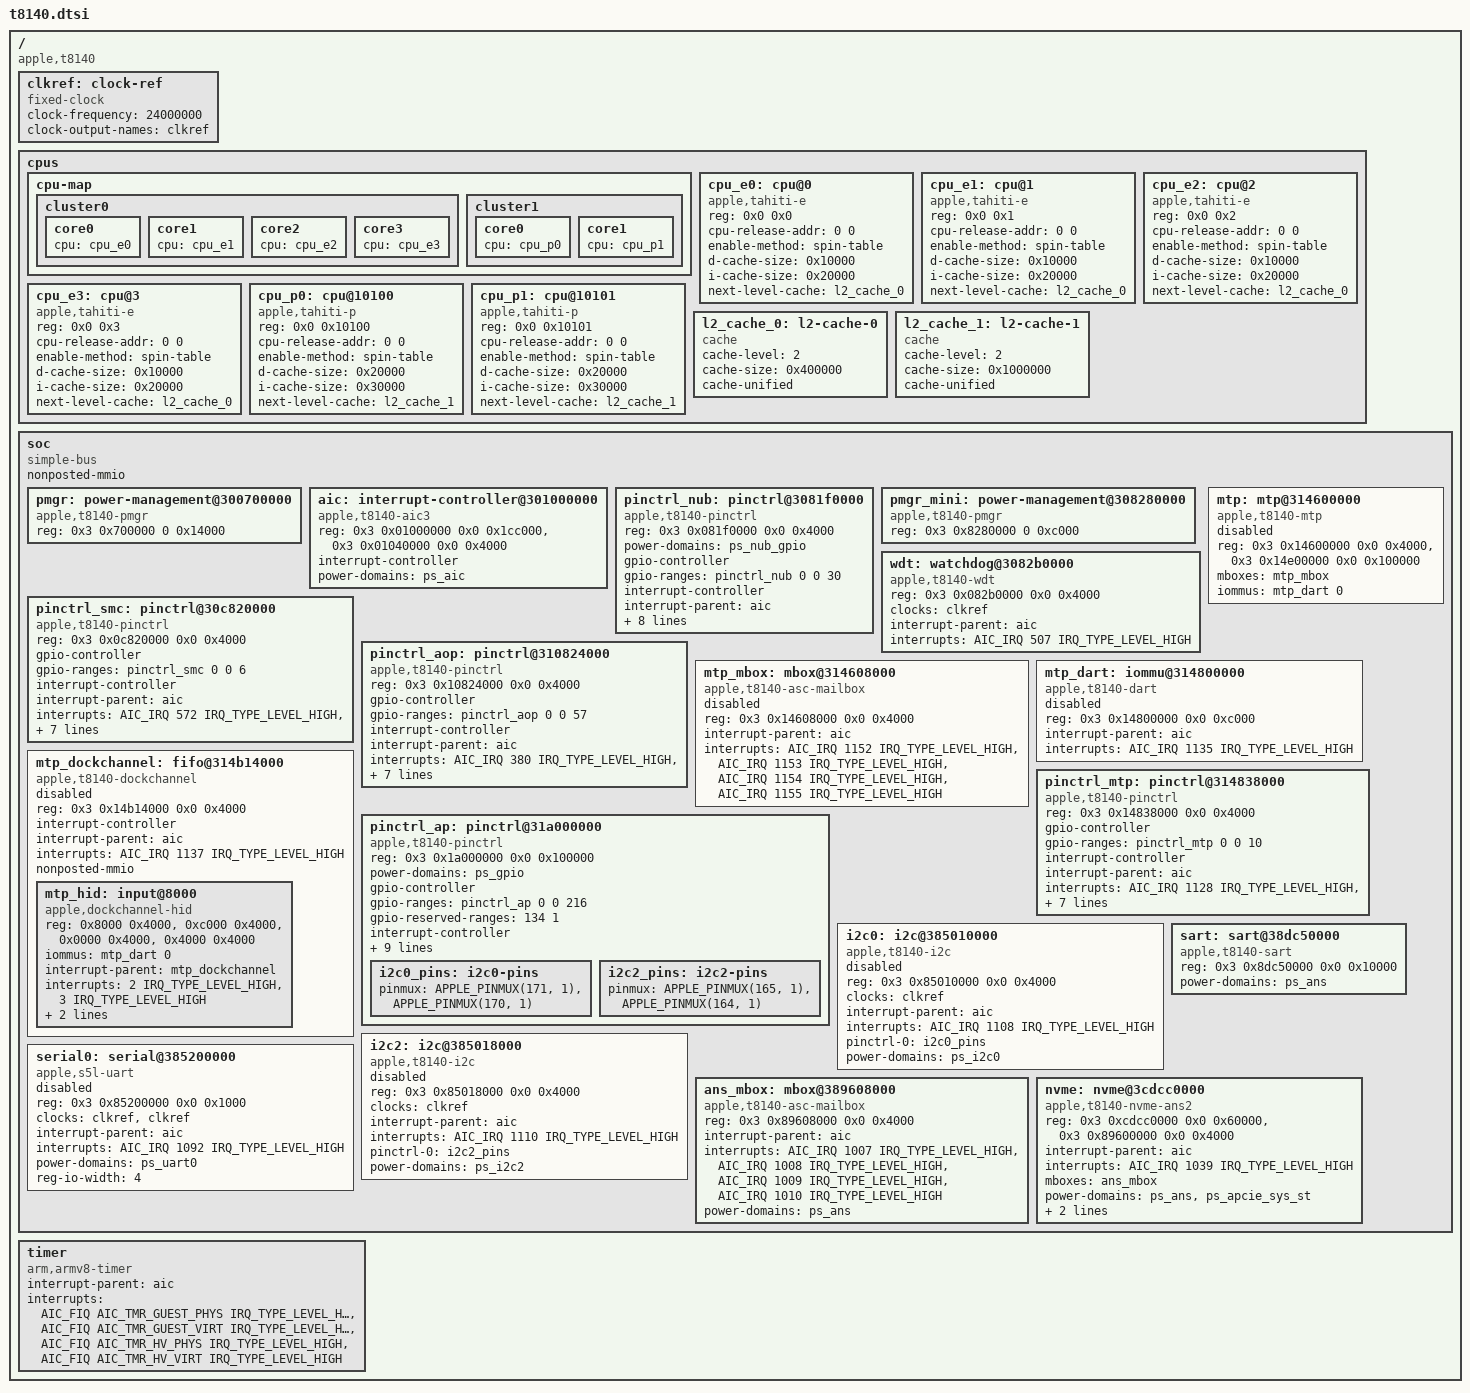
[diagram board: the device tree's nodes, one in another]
// SPDX-License-Identifier: GPL-2.0+ OR MIT
/*
 * Apple T8140 "A18 Pro" SoC
 *
 * Copyright The Asahi Linux Contributors
 */

#include <dt-bindings/interrupt-controller/apple-aic.h>
#include <dt-bindings/interrupt-controller/irq.h>
#include <dt-bindings/pinctrl/apple.h>

/ {
	compatible = "apple,t8140", "apple,arm-platform";

	#address-cells = <2>;
	#size-cells = <2>;

	clkref: clock-ref {
		compatible = "fixed-clock";
		#clock-cells = <0>;
		clock-frequency = <24000000>;
		clock-output-names = "clkref";
	};

	cpus {
		#address-cells = <2>;
		#size-cells = <0>;

		cpu-map {
			cluster0 {
				core0 {
					cpu = <&cpu_e0>;
				};

				core1 {
					cpu = <&cpu_e1>;
				};

				core2 {
					cpu = <&cpu_e2>;
				};

				core3 {
					cpu = <&cpu_e3>;
				};
			};

			cluster1 {
				core0 {
					cpu = <&cpu_p0>;
				};

				core1 {
					cpu = <&cpu_p1>;
				};
			};
		};

		cpu_e0: cpu@0 {
			device_type = "cpu";
			compatible = "apple,tahiti-e";
			reg = <0x0 0x0>;
			cpu-release-addr = <0 0>;
			enable-method = "spin-table";

			d-cache-size = <0x10000>;
			i-cache-size = <0x20000>;
			next-level-cache = <&l2_cache_0>;
		};

		cpu_e1: cpu@1 {
			device_type = "cpu";
			compatible = "apple,tahiti-e";
			reg = <0x0 0x1>;
			cpu-release-addr = <0 0>;
			enable-method = "spin-table";

			d-cache-size = <0x10000>;
			i-cache-size = <0x20000>;
			next-level-cache = <&l2_cache_0>;
		};

		cpu_e2: cpu@2 {
			device_type = "cpu";
			compatible = "apple,tahiti-e";
			reg = <0x0 0x2>;
			cpu-release-addr = <0 0>;
			enable-method = "spin-table";

			d-cache-size = <0x10000>;
			i-cache-size = <0x20000>;
			next-level-cache = <&l2_cache_0>;
		};

		cpu_e3: cpu@3 {
			device_type = "cpu";
			compatible = "apple,tahiti-e";
			reg = <0x0 0x3>;
			cpu-release-addr = <0 0>;
			enable-method = "spin-table";

			d-cache-size = <0x10000>;
			i-cache-size = <0x20000>;
			next-level-cache = <&l2_cache_0>;
		};

		cpu_p0: cpu@10100 {
			device_type = "cpu";
			compatible = "apple,tahiti-p";
			reg = <0x0 0x10100>;
			cpu-release-addr = <0 0>;
			enable-method = "spin-table";

			d-cache-size = <0x20000>;
			i-cache-size = <0x30000>;
			next-level-cache = <&l2_cache_1>;
		};

		cpu_p1: cpu@10101 {
			device_type = "cpu";
			compatible = "apple,tahiti-p";
			reg = <0x0 0x10101>;
			cpu-release-addr = <0 0>;
			enable-method = "spin-table";

			d-cache-size = <0x20000>;
			i-cache-size = <0x30000>;
			next-level-cache = <&l2_cache_1>;
		};

		l2_cache_0: l2-cache-0 {
			compatible = "cache";
			cache-level = <2>;
			cache-size = <0x400000>;
			cache-unified;
		};

		l2_cache_1: l2-cache-1 {
			compatible = "cache";
			cache-level = <2>;
			cache-size = <0x1000000>;
			cache-unified;
		};
	};

	soc: soc {
		compatible = "simple-bus";
		ranges;
		#address-cells = <2>;
		nonposted-mmio;
		#size-cells = <2>;

		pmgr: power-management@300700000 {
			compatible = "apple,t8140-pmgr", "apple,t8103-pmgr",
			             "syscon", "simple-mfd";
			reg = <0x3 0x700000 0 0x14000>;
			#address-cells = <1>;
			#size-cells = <1>;
			/* child nodes are added in t8140-pmgr.dtsi */
		};

		aic: interrupt-controller@301000000 {
			compatible = "apple,t8140-aic3", "apple,t8122-aic3";
			reg = <0x3 0x01000000 0x0 0x1cc000>,
			      <0x3 0x01040000 0x0 0x4000>;
			reg-names = "core", "event";
			#interrupt-cells = <3>;
			interrupt-controller;
			power-domains = <&ps_aic>;
		};

		pinctrl_nub: pinctrl@3081f0000 {
			compatible = "apple,t8140-pinctrl";
			reg = <0x3 0x081f0000 0x0 0x4000>;
			power-domains = <&ps_nub_gpio>;

			gpio-controller;
			#gpio-cells = <2>;
			gpio-ranges = <&pinctrl_nub 0 0 30>;

			interrupt-controller;
			#interrupt-cells = <2>;
			interrupt-parent = <&aic>;
			interrupts = <AIC_IRQ 473 IRQ_TYPE_LEVEL_HIGH>,
			             <AIC_IRQ 474 IRQ_TYPE_LEVEL_HIGH>,
			             <AIC_IRQ 475 IRQ_TYPE_LEVEL_HIGH>,
			             <AIC_IRQ 476 IRQ_TYPE_LEVEL_HIGH>,
			             <AIC_IRQ 477 IRQ_TYPE_LEVEL_HIGH>,
			             <AIC_IRQ 478 IRQ_TYPE_LEVEL_HIGH>,
			             <AIC_IRQ 479 IRQ_TYPE_LEVEL_HIGH>;

			apple,npins = <30>;
		};

		pmgr_mini: power-management@308280000 {
			compatible = "apple,t8140-pmgr", "apple,t8103-pmgr",
			             "syscon", "simple-mfd";
			reg = <0x3 0x8280000 0 0xc000>;
			#address-cells = <1>;
			#size-cells = <1>;
			/* child nodes are added in t8140-pmgr.dtsi */
		};

		wdt: watchdog@3082b0000 {
			compatible = "apple,t8140-wdt", "apple,t8103-wdt";
			reg = <0x3 0x082b0000 0x0 0x4000>;
			clocks = <&clkref>;
			interrupt-parent = <&aic>;
			interrupts = <AIC_IRQ 507 IRQ_TYPE_LEVEL_HIGH>;
		};

		pinctrl_smc: pinctrl@30c820000 {
			compatible = "apple,t8140-pinctrl";
			reg = <0x3 0x0c820000 0x0 0x4000>;

			gpio-controller;
			#gpio-cells = <2>;
			gpio-ranges = <&pinctrl_smc 0 0 6>;

			interrupt-controller;
			#interrupt-cells = <2>;
			interrupt-parent = <&aic>;
			interrupts = <AIC_IRQ 572 IRQ_TYPE_LEVEL_HIGH>,
			             <AIC_IRQ 573 IRQ_TYPE_LEVEL_HIGH>,
			             <AIC_IRQ 574 IRQ_TYPE_LEVEL_HIGH>,
			             <AIC_IRQ 575 IRQ_TYPE_LEVEL_HIGH>,
			             <AIC_IRQ 576 IRQ_TYPE_LEVEL_HIGH>,
			             <AIC_IRQ 577 IRQ_TYPE_LEVEL_HIGH>,
			             <AIC_IRQ 578 IRQ_TYPE_LEVEL_HIGH>;

			apple,npins = <6>;
		};

		pinctrl_aop: pinctrl@310824000 {
			compatible = "apple,t8140-pinctrl";
			reg = <0x3 0x10824000 0x0 0x4000>;

			gpio-controller;
			#gpio-cells = <2>;
			gpio-ranges = <&pinctrl_aop 0 0 57>;

			interrupt-controller;
			#interrupt-cells = <2>;
			interrupt-parent = <&aic>;
			interrupts = <AIC_IRQ 380 IRQ_TYPE_LEVEL_HIGH>,
			             <AIC_IRQ 381 IRQ_TYPE_LEVEL_HIGH>,
			             <AIC_IRQ 382 IRQ_TYPE_LEVEL_HIGH>,
			             <AIC_IRQ 383 IRQ_TYPE_LEVEL_HIGH>,
			             <AIC_IRQ 384 IRQ_TYPE_LEVEL_HIGH>,
			             <AIC_IRQ 385 IRQ_TYPE_LEVEL_HIGH>,
			             <AIC_IRQ 386 IRQ_TYPE_LEVEL_HIGH>;

			apple,npins = <57>;
		};

		mtp: mtp@314600000 {
			compatible = "apple,t8140-mtp",
			             "apple,t8140-rtk-helper-asc4", "apple,mtp",
			             "apple,rtk-helper-asc4";
			reg = <0x3 0x14600000 0x0 0x4000>,
			      <0x3 0x14e00000 0x0 0x100000>;
			reg-names = "asc", "sram";
			mboxes = <&mtp_mbox>;
			iommus = <&mtp_dart 0>;
			#helper-cells = <0>;

			status = "disabled";
		};

		mtp_mbox: mbox@314608000 {
			compatible = "apple,t8140-asc-mailbox",
			             "apple,asc-mailbox-v4";
			reg = <0x3 0x14608000 0x0 0x4000>;
			interrupt-parent = <&aic>;
			interrupts = <AIC_IRQ 1152 IRQ_TYPE_LEVEL_HIGH>,
			             <AIC_IRQ 1153 IRQ_TYPE_LEVEL_HIGH>,
			             <AIC_IRQ 1154 IRQ_TYPE_LEVEL_HIGH>,
			             <AIC_IRQ 1155 IRQ_TYPE_LEVEL_HIGH>;
			interrupt-names = "send-empty", "send-not-empty",
			                  "recv-empty", "recv-not-empty";
			#mbox-cells = <0>;

			status = "disabled";
		};

		mtp_dart: iommu@314800000 {
			compatible = "apple,t8140-dart", "apple,t8110-dart";
			reg = <0x3 0x14800000 0x0 0xc000>;
			interrupt-parent = <&aic>;
			interrupts = <AIC_IRQ 1135 IRQ_TYPE_LEVEL_HIGH>;
			#iommu-cells = <1>;

			status = "disabled";
		};

		pinctrl_mtp: pinctrl@314838000 {
			compatible = "apple,t8140-pinctrl";
			reg = <0x3 0x14838000 0x0 0x4000>;

			gpio-controller;
			#gpio-cells = <2>;
			gpio-ranges = <&pinctrl_mtp 0 0 10>;

			interrupt-controller;
			#interrupt-cells = <2>;
			interrupt-parent = <&aic>;
			interrupts = <AIC_IRQ 1128 IRQ_TYPE_LEVEL_HIGH>,
			             <AIC_IRQ 1129 IRQ_TYPE_LEVEL_HIGH>,
			             <AIC_IRQ 1130 IRQ_TYPE_LEVEL_HIGH>,
			             <AIC_IRQ 1131 IRQ_TYPE_LEVEL_HIGH>,
			             <AIC_IRQ 1132 IRQ_TYPE_LEVEL_HIGH>,
			             <AIC_IRQ 1133 IRQ_TYPE_LEVEL_HIGH>,
			             <AIC_IRQ 1134 IRQ_TYPE_LEVEL_HIGH>;

			apple,npins = <10>;
		};

		mtp_dockchannel: fifo@314b14000 {
			compatible = "apple,t8140-dockchannel",
			             "apple,dockchannel";
			reg = <0x3 0x14b14000 0x0 0x4000>;
			reg-names = "irq";
			ranges = <0 0x3 0x14b28000 0x20000>;

			interrupt-controller;
			#interrupt-cells = <2>;
			interrupt-parent = <&aic>;
			interrupts = <AIC_IRQ 1137 IRQ_TYPE_LEVEL_HIGH>;

			nonposted-mmio;
			#address-cells = <1>;
			#size-cells = <1>;

			status = "disabled";

			mtp_hid: input@8000 {
				compatible = "apple,dockchannel-hid";
				reg = <0x8000 0x4000>,
				      <0xc000 0x4000>,
				      <0x0000 0x4000>,
				      <0x4000 0x4000>;
				reg-names = "config", "data",
				            "rmt-config", "rmt-data";
				iommus = <&mtp_dart 0>;
				interrupt-parent = <&mtp_dockchannel>;
				interrupts = <2 IRQ_TYPE_LEVEL_HIGH>,
				             <3 IRQ_TYPE_LEVEL_HIGH>;
				interrupt-names = "tx", "rx";

				apple,fifo-size = <0x800>;
				apple,helper-cpu = <&mtp>;
			};
		};

		pinctrl_ap: pinctrl@31a000000 {
			compatible = "apple,t8140-pinctrl";
			reg = <0x3 0x1a000000 0x0 0x100000>;
			power-domains = <&ps_gpio>;

			gpio-controller;
			#gpio-cells = <2>;
			gpio-ranges = <&pinctrl_ap 0 0 216>;
			gpio-reserved-ranges = <134 1>;

			interrupt-controller;
			#interrupt-cells = <2>;
			interrupt-parent = <&aic>;
			interrupts = <AIC_IRQ 263 IRQ_TYPE_LEVEL_HIGH>,
			             <AIC_IRQ 264 IRQ_TYPE_LEVEL_HIGH>,
			             <AIC_IRQ 265 IRQ_TYPE_LEVEL_HIGH>,
			             <AIC_IRQ 266 IRQ_TYPE_LEVEL_HIGH>,
			             <AIC_IRQ 267 IRQ_TYPE_LEVEL_HIGH>,
			             <AIC_IRQ 268 IRQ_TYPE_LEVEL_HIGH>,
			             <AIC_IRQ 269 IRQ_TYPE_LEVEL_HIGH>;

			apple,npins = <216>;

			i2c0_pins: i2c0-pins {
				pinmux = <APPLE_PINMUX(171, 1)>,
				         <APPLE_PINMUX(170, 1)>;
			};

			i2c2_pins: i2c2-pins {
				pinmux = <APPLE_PINMUX(165, 1)>,
				         <APPLE_PINMUX(164, 1)>;
			};
		};

		i2c0: i2c@385010000 {
			compatible = "apple,t8140-i2c", "apple,t8103-i2c";
			reg = <0x3 0x85010000 0x0 0x4000>;
			clocks = <&clkref>;
			interrupt-parent = <&aic>;
			interrupts = <AIC_IRQ 1108 IRQ_TYPE_LEVEL_HIGH>;
			pinctrl-0 = <&i2c0_pins>;
			pinctrl-names = "default";
			#address-cells = <0x1>;
			#size-cells = <0x0>;
			power-domains = <&ps_i2c0>;

			status = "disabled";
		};

		i2c2: i2c@385018000 {
			compatible = "apple,t8140-i2c", "apple,t8103-i2c";
			reg = <0x3 0x85018000 0x0 0x4000>;
			clocks = <&clkref>;
			interrupt-parent = <&aic>;
			interrupts = <AIC_IRQ 1110 IRQ_TYPE_LEVEL_HIGH>;
			pinctrl-0 = <&i2c2_pins>;
			pinctrl-names = "default";
			#address-cells = <0x1>;
			#size-cells = <0x0>;
			power-domains = <&ps_i2c2>;

			status = "disabled";
		};

		serial0: serial@385200000 {
			compatible = "apple,s5l-uart";
			reg = <0x3 0x85200000 0x0 0x1000>;
			clocks = <&clkref>, <&clkref>;
			clock-names = "uart", "clk_uart_baud0";
			interrupt-parent = <&aic>;
			interrupts = <AIC_IRQ 1092 IRQ_TYPE_LEVEL_HIGH>;
			power-domains = <&ps_uart0>;
			reg-io-width = <4>;

			status = "disabled";
		};

		ans_mbox: mbox@389608000 {
			compatible = "apple,t8140-asc-mailbox",
				     "apple,asc-mailbox-v4";
			reg = <0x3 0x89608000 0x0 0x4000>;

			interrupt-parent = <&aic>;
			interrupts = <AIC_IRQ 1007 IRQ_TYPE_LEVEL_HIGH>,
				     <AIC_IRQ 1008 IRQ_TYPE_LEVEL_HIGH>,
				     <AIC_IRQ 1009 IRQ_TYPE_LEVEL_HIGH>,
				     <AIC_IRQ 1010 IRQ_TYPE_LEVEL_HIGH>;
			interrupt-names = "send-empty", "send-not-empty",
					  "recv-empty", "recv-not-empty";

			#mbox-cells = <0>;
			power-domains = <&ps_ans>;
		};

		sart: sart@38dc50000 {
			compatible = "apple,t8140-sart", "apple,t6000-sart";
			reg = <0x3 0x8dc50000 0x0 0x10000>;
			power-domains = <&ps_ans>;
		};

		nvme: nvme@3cdcc0000 {
			compatible = "apple,t8140-nvme-ans2",
				     "apple,t8132-nvme-ans2";
			reg = <0x3 0xcdcc0000 0x0 0x60000>,
			      <0x3 0x89600000 0x0 0x4000>;
			reg-names = "nvme", "ans";

			interrupt-parent = <&aic>;
			interrupts = <AIC_IRQ 1039 IRQ_TYPE_LEVEL_HIGH>;

			mboxes = <&ans_mbox>;

			power-domains = <&ps_ans>, <&ps_apcie_sys_st>;
			power-domain-names = "ans", "apcie0";
			resets = <&ps_ans>;

			apple,sart = <&sart>;
		};
	};

	timer {
		compatible = "arm,armv8-timer";
		interrupt-parent = <&aic>;
		interrupts = <AIC_FIQ AIC_TMR_GUEST_PHYS IRQ_TYPE_LEVEL_HIGH>,
		             <AIC_FIQ AIC_TMR_GUEST_VIRT IRQ_TYPE_LEVEL_HIGH>,
		             <AIC_FIQ AIC_TMR_HV_PHYS IRQ_TYPE_LEVEL_HIGH>,
		             <AIC_FIQ AIC_TMR_HV_VIRT IRQ_TYPE_LEVEL_HIGH>;
		interrupt-names = "phys", "virt", "hyp-phys", "hyp-virt";
	};
};

#include "t8140-pmgr.dtsi"
